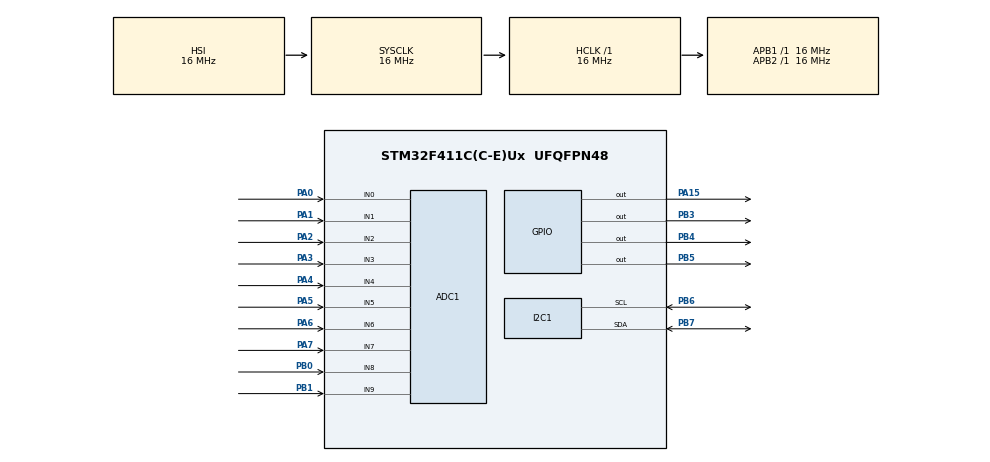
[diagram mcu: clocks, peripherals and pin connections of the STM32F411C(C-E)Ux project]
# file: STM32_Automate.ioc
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ADC1.Channel-0\#ChannelRegularConversion=ADC_CHANNEL_0
ADC1.Channel-1\#ChannelRegularConversion=ADC_CHANNEL_1
ADC1.Channel-2\#ChannelRegularConversion=ADC_CHANNEL_2
ADC1.Channel-3\#ChannelRegularConversion=ADC_CHANNEL_3
ADC1.Channel-4\#ChannelRegularConversion=ADC_CHANNEL_4
ADC1.Channel-5\#ChannelRegularConversion=ADC_CHANNEL_5
ADC1.Channel-6\#ChannelRegularConversion=ADC_CHANNEL_6
ADC1.Channel-7\#ChannelRegularConversion=ADC_CHANNEL_7
ADC1.ContinuousConvMode=ENABLE
ADC1.DMAContinuousRequests=ENABLE
ADC1.EOCSelection=ADC_EOC_SINGLE_CONV
ADC1.NbrOfConversion=8
ADC1.NbrOfConversionFlag=1
ADC1.Rank-0\#ChannelRegularConversion=1
ADC1.Rank-1\#ChannelRegularConversion=2
ADC1.Rank-2\#ChannelRegularConversion=3
ADC1.Rank-3\#ChannelRegularConversion=4
ADC1.Rank-4\#ChannelRegularConversion=5
ADC1.Rank-5\#ChannelRegularConversion=6
ADC1.Rank-6\#ChannelRegularConversion=7
ADC1.Rank-7\#ChannelRegularConversion=8
ADC1.SamplingTime-0\#ChannelRegularConversion=ADC_SAMPLETIME_15CYCLES
ADC1.SamplingTime-1\#ChannelRegularConversion=ADC_SAMPLETIME_15CYCLES
ADC1.SamplingTime-2\#ChannelRegularConversion=ADC_SAMPLETIME_15CYCLES
ADC1.SamplingTime-3\#ChannelRegularConversion=ADC_SAMPLETIME_15CYCLES
ADC1.SamplingTime-4\#ChannelRegularConversion=ADC_SAMPLETIME_15CYCLES
ADC1.SamplingTime-5\#ChannelRegularConversion=ADC_SAMPLETIME_15CYCLES
ADC1.SamplingTime-6\#ChannelRegularConversion=ADC_SAMPLETIME_15CYCLES
ADC1.SamplingTime-7\#ChannelRegularConversion=ADC_SAMPLETIME_15CYCLES
ADC1.ScanConvMode=ENABLE
ADC1.master=1
Dma.ADC1.0.Direction=DMA_PERIPH_TO_MEMORY
Dma.ADC1.0.FIFOMode=DMA_FIFOMODE_DISABLE
Dma.ADC1.0.Instance=DMA2_Stream0
Dma.ADC1.0.MemDataAlignment=DMA_MDATAALIGN_HALFWORD
Dma.ADC1.0.MemInc=DMA_MINC_ENABLE
Dma.ADC1.0.Mode=DMA_CIRCULAR
Dma.ADC1.0.PeriphDataAlignment=DMA_PDATAALIGN_HALFWORD
Dma.ADC1.0.PeriphInc=DMA_PINC_DISABLE
Dma.ADC1.0.Priority=DMA_PRIORITY_LOW
Dma.Request0=ADC1
I2C1.I2C_Mode=I2C_Fast
Mcu.Family=STM32F4
Mcu.Name=STM32F411C(C-E)Ux
Mcu.Package=UFQFPN48
NVIC.DMA2_Stream0_IRQn=true\:0\:0\:false\:false\:true\:false\:true\:true
NVIC.PriorityGroup=NVIC_PRIORITYGROUP_4
PA0-WKUP.Signal=ADCx_IN0
PA1.Signal=ADCx_IN1
PA15.Signal=GPIO_Output
PA2.Signal=ADCx_IN2
PA3.Signal=ADCx_IN3
PA4.Signal=ADCx_IN4
PA5.Signal=ADCx_IN5
PA6.Signal=ADCx_IN6
PA7.Signal=ADCx_IN7
PB0.Signal=ADCx_IN8
PB1.Signal=ADCx_IN9
PB3.Signal=GPIO_Output
PB4.Signal=GPIO_Output
PB5.Signal=GPIO_Output
PB6.Mode=I2C
PB6.Signal=I2C1_SCL
PB7.Mode=I2C
PB7.Signal=I2C1_SDA
PH0\ -\ OSC_IN.Mode=HSE-External-Oscillator
PH0\ -\ OSC_IN.Signal=RCC_OSC_IN
PH1\ -\ OSC_OUT.Mode=HSE-External-Oscillator
PH1\ -\ OSC_OUT.Signal=RCC_OSC_OUT
ProjectManager.HeapSize=0x200
ProjectManager.StackSize=0x400
ProjectManager.TargetToolchain=STM32CubeIDE
RCC.AHBFreq_Value=16000000
RCC.APB1Freq_Value=16000000
RCC.APB2Freq_Value=16000000
RCC.CortexFreq_Value=16000000
RCC.HSE_VALUE=25000000
RCC.HSI_VALUE=16000000
RCC.LSE_VALUE=32768
RCC.SYSCLKFreq_VALUE=16000000
RCC.VCOOutputFreq_Value=192000000
SH.ADCx_IN0.0=ADC1_IN0,IN0
SH.ADCx_IN1.0=ADC1_IN1,IN1
SH.ADCx_IN2.0=ADC1_IN2,IN2
SH.ADCx_IN3.0=ADC1_IN3,IN3
SH.ADCx_IN4.0=ADC1_IN4,IN4
SH.ADCx_IN5.0=ADC1_IN5,IN5
SH.ADCx_IN6.0=ADC1_IN6,IN6
SH.ADCx_IN7.0=ADC1_IN7,IN7
SH.ADCx_IN8.0=ADC1_IN8,IN8
SH.ADCx_IN9.0=ADC1_IN9,IN9
board=custom

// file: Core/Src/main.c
/* USER CODE BEGIN Header */
/**
  ******************************************************************************
  * @file           : main.c
  * @brief          : Main program body - 4 POTS + 4 INPUTS + RELAY LOGIC
  ******************************************************************************
  * @attention
  *
  * Copyright (c) 2026 STMicroelectronics.
  * All rights reserved.
  *
  * This software is licensed under terms that can be found in the LICENSE file
  * in the root directory of this software component.
  * If no LICENSE file comes with this software, it is provided AS-IS.
  *
  ******************************************************************************
  */
/* USER CODE END Header */
#include "main.h"
#include "liquidcrystal_i2c.h"
#include <stdlib.h>

ADC_HandleTypeDef hadc1;
DMA_HandleTypeDef hdma_adc1;

I2C_HandleTypeDef hi2c1;

/* USER CODE BEGIN PV */
/* ADC buffer - 8 channels (4 pots + 4 inputs) */
uint16_t adc_values[8];

/* Percentage values */
uint8_t adc_percent[8];

/* Channel mapping */
uint32_t adc_channels[8] = {
    ADC_CHANNEL_0,  // PA0 - Pot 0
    ADC_CHANNEL_1,  // PA1 - Pot 1
    ADC_CHANNEL_2,  // PA2 - Pot 2
    ADC_CHANNEL_3,  // PA3 - Pot 3
    ADC_CHANNEL_5,  // PA5 - Input 0
    ADC_CHANNEL_6,  // PA6 - Input 1
    ADC_CHANNEL_7,  // PA7 - Input 2
    ADC_CHANNEL_4   // PA4 - Input 3
};
/* USER CODE END PV */

void SystemClock_Config(void);
static void MX_GPIO_Init(void);
static void MX_DMA_Init(void);
static void MX_ADC1_Init(void);
static void MX_I2C1_Init(void);
void read_all_adc_polling(void);
void calculate_percentages(void);
void display_on_lcd(void);

/* USER CODE BEGIN 0 */

/**
  * @brief Read all 8 ADC channels using polling mode
  */
void read_all_adc_polling(void)
{
    ADC_ChannelConfTypeDef sConfig = {0};

    for (int i = 0; i < 8; i++) {
        /* Configure the channel */
        sConfig.Channel = adc_channels[i];
        sConfig.Rank = 1;
        sConfig.SamplingTime = ADC_SAMPLETIME_15CYCLES;
        HAL_ADC_ConfigChannel(&hadc1, &sConfig);

        /* Read the value */
        HAL_ADC_Start(&hadc1);
        HAL_ADC_PollForConversion(&hadc1, 10);
        adc_values[i] = HAL_ADC_GetValue(&hadc1);
        HAL_ADC_Stop(&hadc1);
    }
}

/**
  * @brief Convert ADC values to percentages (0-4095 → 0-100%)
  */
void calculate_percentages(void)
{
    for (int i = 0; i < 8; i++) {
        /* Formula: percentage = (adc_value * 100) / 4095 */
        adc_percent[i] = (uint8_t)((adc_values[i] * 100) / 4095);
    }
}

/**
  * @brief Display potentiometers and inputs with cycling
  * Cycles between: P0-P1 with I0-I1, then P2-P3 with I2-I3
  */
void display_on_lcd(void)
{
    static uint32_t cycle_counter = 0;
    char buffer[20];

    cycle_counter++;

    if (cycle_counter < 20) {  /* Show P0-P1 with I0-I1 for 2 seconds */
        /* Line 1: P0: XX% | I0: XX% */
        HD44780_SetCursor(0, 0);
        itoa(adc_percent[0], buffer, 10);
        HD44780_PrintStr("P0:");
        HD44780_PrintStr(buffer);
        HD44780_PrintStr("%   ");

        itoa(adc_percent[4], buffer, 10);
        HD44780_PrintStr("I0:");
        HD44780_PrintStr(buffer);
        HD44780_PrintStr("%   ");

        /* Line 2: P1: XX% | I1: XX% */
        HD44780_SetCursor(0, 1);
        itoa(adc_percent[1], buffer, 10);
        HD44780_PrintStr("P1:");
        HD44780_PrintStr(buffer);
        HD44780_PrintStr("%   ");

        itoa(adc_percent[5], buffer, 10);
        HD44780_PrintStr("I1:");
        HD44780_PrintStr(buffer);
        HD44780_PrintStr("%   ");
    }
    else if (cycle_counter < 40) {  /* Show P2-P3 with I2-I3 for 2 seconds */
        /* Line 1: P2: XX% | I2: XX% */
        HD44780_SetCursor(0, 0);
        itoa(adc_percent[2], buffer, 10);
        HD44780_PrintStr("P2:");
        HD44780_PrintStr(buffer);
        HD44780_PrintStr("%   ");

        itoa(adc_percent[6], buffer, 10);
        HD44780_PrintStr("I2:");
        HD44780_PrintStr(buffer);
        HD44780_PrintStr("%   ");

        /* Line 2: P3: XX% | I3: XX% */
        HD44780_SetCursor(0, 1);
        itoa(adc_percent[3], buffer, 10);
        HD44780_PrintStr("P3:");
        HD44780_PrintStr(buffer);
        HD44780_PrintStr("%   ");

        itoa(adc_percent[7], buffer, 10);
        HD44780_PrintStr("I3:");
        HD44780_PrintStr(buffer);
        HD44780_PrintStr("%   ");
    }
    else {
        cycle_counter = 0;  /* Reset cycle */
    }
}

/* USER CODE END 0 */

int main(void)
{

  /* MCU Configuration--------------------------------------------------------*/

  /* Reset of all peripherals, Initializes the Flash interface and the Systick. */
  HAL_Init();

  /* Configure the system clock */
  SystemClock_Config();

  /* Initialize all configured peripherals */
  MX_GPIO_Init();
  MX_DMA_Init();
  MX_ADC1_Init();
  MX_I2C1_Init();

  /* Initialize LCD */
  HD44780_Init(2);
  HD44780_Clear();
  HD44780_SetCursor(0, 0);
  HD44780_PrintStr("Automate STM32");
  HAL_Delay(1000);
  HD44780_Clear();

  /* Infinite loop */
  /* USER CODE BEGIN WHILE */
  while (1)
  {
    /* 1. Read all 8 ADC channels */
    read_all_adc_polling();

    /* 2. Calculate percentages */
    calculate_percentages();

    /* 3. Display on LCD (cycling) */
    display_on_lcd();

    /* USER CODE END WHILE */

    /* USER CODE BEGIN 3 */

    HAL_GPIO_WritePin(GPIOB, GPIO_PIN_5, (adc_percent[4] < adc_percent[0]) ? GPIO_PIN_SET : GPIO_PIN_RESET);
    HAL_GPIO_WritePin(GPIOB, GPIO_PIN_4, (adc_percent[5] < adc_percent[1]) ? GPIO_PIN_SET : GPIO_PIN_RESET);
    HAL_GPIO_WritePin(GPIOB, GPIO_PIN_3, (adc_percent[6] < adc_percent[2]) ? GPIO_PIN_SET : GPIO_PIN_RESET);

    HAL_GPIO_WritePin(GPIOA, GPIO_PIN_15, (adc_percent[7] < adc_percent[3]) ? GPIO_PIN_SET : GPIO_PIN_RESET);

    /* Relay 5 (PA12): OFF for now */
    HAL_GPIO_WritePin(GPIOA, GPIO_PIN_12, GPIO_PIN_RESET);

    HAL_Delay(100);

    /* USER CODE END 3 */
  }
  /* USER CODE END 3 */
}

void SystemClock_Config(void)
{
  RCC_OscInitTypeDef RCC_OscInitStruct = {0};
  RCC_ClkInitTypeDef RCC_ClkInitStruct = {0};

  /** Configure the main internal regulator output voltage
  */
  __HAL_RCC_PWR_CLK_ENABLE();
  __HAL_PWR_VOLTAGESCALING_CONFIG(PWR_REGULATOR_VOLTAGE_SCALE1);

  /** Initializes the RCC Oscillators according to the specified parameters
  * in the RCC_OscInitTypeDef structure.
  */
  RCC_OscInitStruct.OscillatorType = RCC_OSCILLATORTYPE_HSI;
  RCC_OscInitStruct.HSIState = RCC_HSI_ON;
  RCC_OscInitStruct.HSICalibrationValue = RCC_HSICALIBRATION_DEFAULT;
  RCC_OscInitStruct.PLL.PLLState = RCC_PLL_NONE;
  if (HAL_RCC_OscConfig(&RCC_OscInitStruct) != HAL_OK)
  {
    Error_Handler();
  }

  /** Initializes the CPU, AHB and APB buses clocks
  */
  RCC_ClkInitStruct.ClockType = RCC_CLOCKTYPE_HCLK|RCC_CLOCKTYPE_SYSCLK
                              |RCC_CLOCKTYPE_PCLK1|RCC_CLOCKTYPE_PCLK2;
  RCC_ClkInitStruct.SYSCLKSource = RCC_SYSCLKSOURCE_HSI;
  RCC_ClkInitStruct.AHBCLKDivider = RCC_SYSCLK_DIV1;
  RCC_ClkInitStruct.APB1CLKDivider = RCC_HCLK_DIV1;
  RCC_ClkInitStruct.APB2CLKDivider = RCC_HCLK_DIV1;

  if (HAL_RCC_ClockConfig(&RCC_ClkInitStruct, FLASH_LATENCY_0) != HAL_OK)
  {
    Error_Handler();
  }
}

static void MX_ADC1_Init(void)
{

  ADC_ChannelConfTypeDef sConfig = {0};

  /** Configure the global features of the ADC (Clock, Resolution, Data Alignment and number of conversion)
  */
  hadc1.Instance = ADC1;
  hadc1.Init.ClockPrescaler = ADC_CLOCK_SYNC_PCLK_DIV2;
  hadc1.Init.Resolution = ADC_RESOLUTION_12B;
  hadc1.Init.ScanConvMode = DISABLE;
  hadc1.Init.ContinuousConvMode = DISABLE;
  hadc1.Init.DiscontinuousConvMode = DISABLE;
  hadc1.Init.ExternalTrigConvEdge = ADC_EXTERNALTRIGCONVEDGE_NONE;
  hadc1.Init.ExternalTrigConv = ADC_SOFTWARE_START;
  hadc1.Init.DataAlign = ADC_DATAALIGN_RIGHT;
  hadc1.Init.NbrOfConversion = 1;
  hadc1.Init.DMAContinuousRequests = DISABLE;
  hadc1.Init.EOCSelection = ADC_EOC_SINGLE_CONV;
  if (HAL_ADC_Init(&hadc1) != HAL_OK)
  {
    Error_Handler();
  }

  sConfig.Channel = ADC_CHANNEL_0;
  sConfig.Rank = 1;
  sConfig.SamplingTime = ADC_SAMPLETIME_15CYCLES;
  if (HAL_ADC_ConfigChannel(&hadc1, &sConfig) != HAL_OK)
  {
    Error_Handler();
  }

}

static void MX_I2C1_Init(void)
{

  hi2c1.Instance = I2C1;
  hi2c1.Init.ClockSpeed = 400000;
  hi2c1.Init.DutyCycle = I2C_DUTYCYCLE_2;
  hi2c1.Init.OwnAddress1 = 0;
  hi2c1.Init.AddressingMode = I2C_ADDRESSINGMODE_7BIT;
  hi2c1.Init.DualAddressMode = I2C_DUALADDRESS_DISABLE;
  hi2c1.Init.OwnAddress2 = 0;
  hi2c1.Init.GeneralCallMode = I2C_GENERALCALL_DISABLE;
  hi2c1.Init.NoStretchMode = I2C_NOSTRETCH_DISABLE;
  if (HAL_I2C_Init(&hi2c1) != HAL_OK)
  {
    Error_Handler();
  }

}

static void MX_DMA_Init(void)
{

  /* DMA controller clock enable */
  __HAL_RCC_DMA2_CLK_ENABLE();

  /* DMA interrupt init */
  /* DMA2_Stream0_IRQn interrupt configuration */
  HAL_NVIC_SetPriority(DMA2_Stream0_IRQn, 0, 0);
  HAL_NVIC_EnableIRQ(DMA2_Stream0_IRQn);

}

static void MX_GPIO_Init(void)
{
  GPIO_InitTypeDef GPIO_InitStruct = {0};

  /* GPIO Ports Clock Enable */
  __HAL_RCC_GPIOH_CLK_ENABLE();
  __HAL_RCC_GPIOA_CLK_ENABLE();
  __HAL_RCC_GPIOB_CLK_ENABLE();

  /*Configure GPIO pin Output Level */
  HAL_GPIO_WritePin(GPIOA, GPIO_PIN_12|GPIO_PIN_15, GPIO_PIN_RESET);

  /*Configure GPIO pin Output Level */
  HAL_GPIO_WritePin(GPIOB, GPIO_PIN_3|GPIO_PIN_4|GPIO_PIN_5, GPIO_PIN_RESET);

  /*Configure GPIO pins : PA12 PA15 */
  GPIO_InitStruct.Pin = GPIO_PIN_12|GPIO_PIN_15;
  GPIO_InitStruct.Mode = GPIO_MODE_OUTPUT_PP;
  GPIO_InitStruct.Pull = GPIO_NOPULL;
  GPIO_InitStruct.Speed = GPIO_SPEED_FREQ_LOW;
  HAL_GPIO_Init(GPIOA, &GPIO_InitStruct);

  /*Configure GPIO pins : PB3 PB4 PB5 */
  GPIO_InitStruct.Pin = GPIO_PIN_3|GPIO_PIN_4|GPIO_PIN_5;
  GPIO_InitStruct.Mode = GPIO_MODE_OUTPUT_PP;
  GPIO_InitStruct.Pull = GPIO_NOPULL;
  GPIO_InitStruct.Speed = GPIO_SPEED_FREQ_LOW;
  HAL_GPIO_Init(GPIOB, &GPIO_InitStruct);

}

void Error_Handler(void)
{
  __disable_irq();
  while (1)
  {
  }
}
